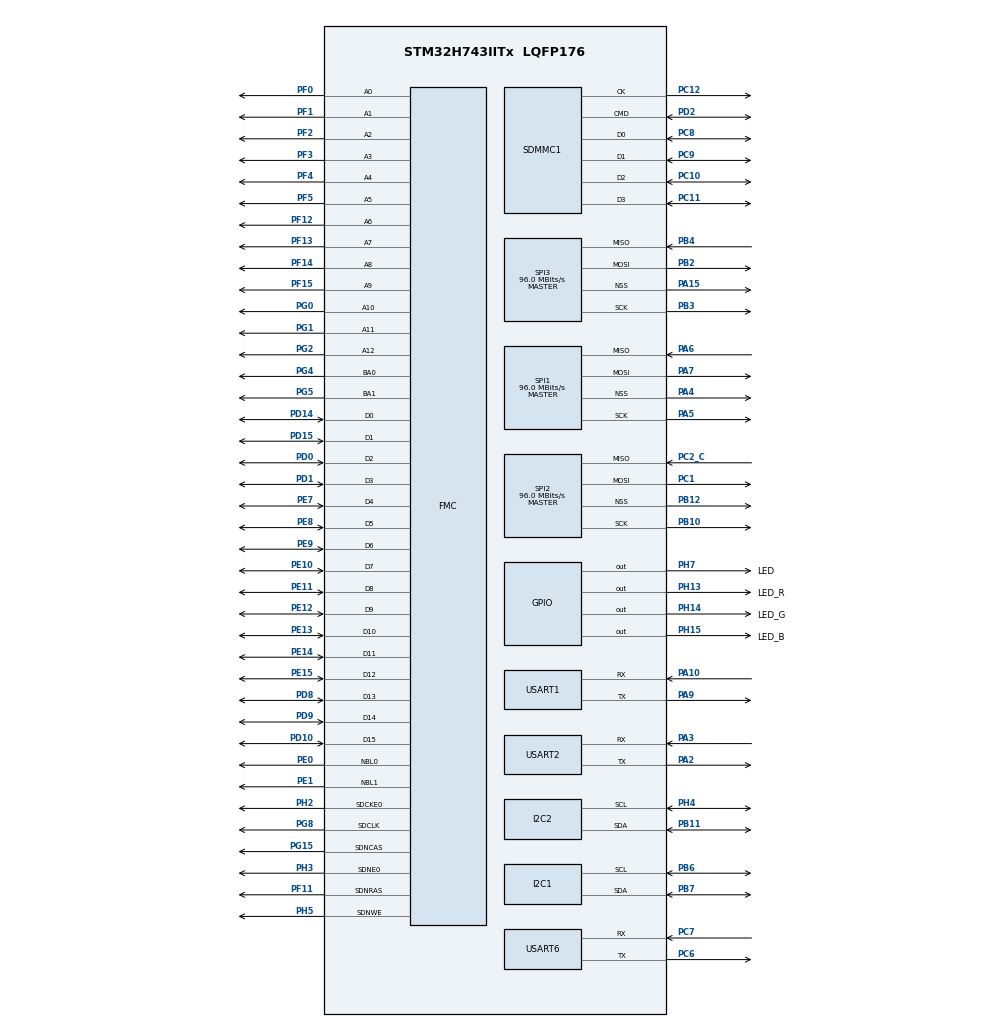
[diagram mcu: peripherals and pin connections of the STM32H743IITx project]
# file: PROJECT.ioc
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CORTEX_M7.CPU_DCache=Enabled
CORTEX_M7.CPU_ICache=Enabled
CORTEX_M7.MPU_Control=MPU_PRIVILEGED_DEFAULT
Dma.Request0=USART1_RX
Dma.Request1=USART1_TX
Dma.USART1_RX.0.Direction=DMA_PERIPH_TO_MEMORY
Dma.USART1_RX.0.EventEnable=DISABLE
Dma.USART1_RX.0.FIFOMode=DMA_FIFOMODE_DISABLE
Dma.USART1_RX.0.Instance=DMA1_Stream0
Dma.USART1_RX.0.MemDataAlignment=DMA_MDATAALIGN_BYTE
Dma.USART1_RX.0.MemInc=DMA_MINC_ENABLE
Dma.USART1_RX.0.Mode=DMA_NORMAL
Dma.USART1_RX.0.PeriphDataAlignment=DMA_PDATAALIGN_BYTE
Dma.USART1_RX.0.PeriphInc=DMA_PINC_DISABLE
Dma.USART1_RX.0.Polarity=HAL_DMAMUX_REQ_GEN_RISING
Dma.USART1_RX.0.Priority=DMA_PRIORITY_LOW
Dma.USART1_RX.0.RequestNumber=1
Dma.USART1_RX.0.SignalID=NONE
Dma.USART1_RX.0.SyncEnable=DISABLE
Dma.USART1_RX.0.SyncPolarity=HAL_DMAMUX_SYNC_NO_EVENT
Dma.USART1_RX.0.SyncRequestNumber=1
Dma.USART1_RX.0.SyncSignalID=NONE
Dma.USART1_TX.1.Direction=DMA_MEMORY_TO_PERIPH
Dma.USART1_TX.1.EventEnable=DISABLE
Dma.USART1_TX.1.FIFOMode=DMA_FIFOMODE_DISABLE
Dma.USART1_TX.1.Instance=DMA1_Stream1
Dma.USART1_TX.1.MemDataAlignment=DMA_MDATAALIGN_BYTE
Dma.USART1_TX.1.MemInc=DMA_MINC_ENABLE
Dma.USART1_TX.1.Mode=DMA_NORMAL
Dma.USART1_TX.1.PeriphDataAlignment=DMA_PDATAALIGN_BYTE
Dma.USART1_TX.1.PeriphInc=DMA_PINC_DISABLE
Dma.USART1_TX.1.Polarity=HAL_DMAMUX_REQ_GEN_RISING
Dma.USART1_TX.1.Priority=DMA_PRIORITY_LOW
Dma.USART1_TX.1.RequestNumber=1
Dma.USART1_TX.1.SignalID=NONE
Dma.USART1_TX.1.SyncEnable=DISABLE
Dma.USART1_TX.1.SyncPolarity=HAL_DMAMUX_SYNC_NO_EVENT
Dma.USART1_TX.1.SyncRequestNumber=1
Dma.USART1_TX.1.SyncSignalID=NONE
FATFS.USE_DMA_CODE_SD=1
FATFS._CODE_PAGE=437
FATFS._USE_LFN=2
FMC.CASLatency1=FMC_SDRAM_CAS_LATENCY_3
FMC.ColumnBitsNumber1=FMC_SDRAM_COLUMN_BITS_NUM_9
FMC.ExitSelfRefreshDelay1=9
FMC.LoadToActiveDelay1=1
FMC.RCDDelay1=3
FMC.RPDelay1=3
FMC.ReadBurst1=FMC_SDRAM_RBURST_ENABLE
FMC.RowCycleDelay1=8
FMC.SDClockPeriod1=FMC_SDRAM_CLOCK_PERIOD_2
FMC.SelfRefreshTime1=6
FMC.WriteRecoveryTime1=3
I2C1.Timing=0x307075B1
I2C2.Timing=0x307075B1
Mcu.Family=STM32H7
Mcu.Name=STM32H743IITx
Mcu.Package=LQFP176
Mdma.MDMA_Channel0.Request0=SDMMC1_END_DATA
Mdma.MDMA_Channel0.RequestsNb=1
Mdma.MDMA_Channel0.SDMMC1_END_DATA.0.BlockCount=0
Mdma.MDMA_Channel0.SDMMC1_END_DATA.0.BlockDataLength=0
Mdma.MDMA_Channel0.SDMMC1_END_DATA.0.BufferTransferLength=1
Mdma.MDMA_Channel0.SDMMC1_END_DATA.0.CircularMode=MDMA_LINEAR_LIST
Mdma.MDMA_Channel0.SDMMC1_END_DATA.0.DataAlignment=MDMA_DATAALIGN_PACKENABLE
Mdma.MDMA_Channel0.SDMMC1_END_DATA.0.DestBlockAddressOffset=0
Mdma.MDMA_Channel0.SDMMC1_END_DATA.0.DestBurst=MDMA_DEST_BURST_SINGLE
Mdma.MDMA_Channel0.SDMMC1_END_DATA.0.DestDataSize=MDMA_DEST_DATASIZE_BYTE
Mdma.MDMA_Channel0.SDMMC1_END_DATA.0.DestinationInc=MDMA_DEST_INC_BYTE
Mdma.MDMA_Channel0.SDMMC1_END_DATA.0.DstAddress=0
Mdma.MDMA_Channel0.SDMMC1_END_DATA.0.Endianness=MDMA_LITTLE_ENDIANNESS_PRESERVE
Mdma.MDMA_Channel0.SDMMC1_END_DATA.0.Instance=MDMA_Channel0
Mdma.MDMA_Channel0.SDMMC1_END_DATA.0.MaskAddress=0
Mdma.MDMA_Channel0.SDMMC1_END_DATA.0.MaskData=0
Mdma.MDMA_Channel0.SDMMC1_END_DATA.0.Priority=MDMA_PRIORITY_LOW
Mdma.MDMA_Channel0.SDMMC1_END_DATA.0.Rank=First
Mdma.MDMA_Channel0.SDMMC1_END_DATA.0.SourceBlockAddressOffset=0
Mdma.MDMA_Channel0.SDMMC1_END_DATA.0.SourceBurst=MDMA_SOURCE_BURST_SINGLE
Mdma.MDMA_Channel0.SDMMC1_END_DATA.0.SourceDataSize=MDMA_SRC_DATASIZE_BYTE
Mdma.MDMA_Channel0.SDMMC1_END_DATA.0.SourceInc=MDMA_SRC_INC_BYTE
Mdma.MDMA_Channel0.SDMMC1_END_DATA.0.SrcAddress=0
Mdma.MDMA_Channel0.SDMMC1_END_DATA.0.TransferTriggerMode=MDMA_BUFFER_TRANSFER
Mdma.RequestSet0=MDMA_Channel0
Mdma.RequestSetsNb=1
NVIC.DMA1_Stream0_IRQn=true\:0\:0\:false\:false\:true\:false\:true\:true
NVIC.DMA1_Stream1_IRQn=true\:0\:0\:false\:false\:true\:false\:true\:true
NVIC.MDMA_IRQn=true\:0\:0\:false\:false\:true\:true\:true\:true
NVIC.PriorityGroup=NVIC_PRIORITYGROUP_4
NVIC.SDMMC1_IRQn=true\:0\:0\:false\:false\:true\:true\:true\:true
NVIC.USART1_IRQn=true\:0\:0\:false\:false\:true\:true\:true\:true
PA10.Mode=Asynchronous
PA10.Signal=USART1_RX
PA13\ (JTMS/SWDIO).Mode=Serial_Wire
PA13\ (JTMS/SWDIO).Signal=DEBUG_JTMS-SWDIO
PA14\ (JTCK/SWCLK).Mode=Serial_Wire
PA14\ (JTCK/SWCLK).Signal=DEBUG_JTCK-SWCLK
PA15\ (JTDI).Mode=NSS_Signal_Hard_Output
PA15\ (JTDI).Signal=SPI3_NSS
PA2.Mode=Asynchronous
PA2.Signal=USART2_TX
PA3.Mode=Asynchronous
PA3.Signal=USART2_RX
PA4.Mode=NSS_Signal_Hard_Output
PA4.Signal=SPI1_NSS
PA5.Mode=Full_Duplex_Master
PA5.Signal=SPI1_SCK
PA6.Mode=Full_Duplex_Master
PA6.Signal=SPI1_MISO
PA7.Mode=Full_Duplex_Master
PA7.Signal=SPI1_MOSI
PA9.Mode=Asynchronous
PA9.Signal=USART1_TX
PB10.Mode=Full_Duplex_Master
PB10.Signal=SPI2_SCK
PB11.Mode=I2C
PB11.Signal=I2C2_SDA
PB12.Mode=NSS_Signal_Hard_Output
PB12.Signal=SPI2_NSS
PB2.Mode=Full_Duplex_Master
PB2.Signal=SPI3_MOSI
PB3\ (JTDO/TRACESWO).Mode=Full_Duplex_Master
PB3\ (JTDO/TRACESWO).Signal=SPI3_SCK
PB4\ (NJTRST).Mode=Full_Duplex_Master
PB4\ (NJTRST).Signal=SPI3_MISO
PB6.Mode=I2C
PB6.Signal=I2C1_SCL
PB7.Mode=I2C
PB7.Signal=I2C1_SDA
PC1.Mode=Full_Duplex_Master
PC1.Signal=SPI2_MOSI
PC10.Mode=SD_4_bits_Wide_bus
PC10.Signal=SDMMC1_D2
PC11.Mode=SD_4_bits_Wide_bus
PC11.Signal=SDMMC1_D3
PC12.Mode=SD_4_bits_Wide_bus
PC12.Signal=SDMMC1_CK
PC14-OSC32_IN\ (OSC32_IN).Mode=LSE-External-Oscillator
PC14-OSC32_IN\ (OSC32_IN).Signal=RCC_OSC32_IN
PC15-OSC32_OUT\ (OSC32_OUT).Mode=LSE-External-Oscillator
PC15-OSC32_OUT\ (OSC32_OUT).Signal=RCC_OSC32_OUT
PC2_C.Mode=Full_Duplex_Master
PC2_C.Signal=SPI2_MISO
PC6.Mode=Asynchronous
PC6.Signal=USART6_TX
PC7.Mode=Asynchronous
PC7.Signal=USART6_RX
PC8.Mode=SD_4_bits_Wide_bus
PC8.Signal=SDMMC1_D0
PC9.Mode=SD_4_bits_Wide_bus
PC9.Signal=SDMMC1_D1
PD0.Signal=FMC_D2_DA2
PD1.Signal=FMC_D3_DA3
PD10.Signal=FMC_D15_DA15
PD14.Signal=FMC_D0_DA0
PD15.Signal=FMC_D1_DA1
PD2.Mode=SD_4_bits_Wide_bus
PD2.Signal=SDMMC1_CMD
PD8.Signal=FMC_D13_DA13
PD9.Signal=FMC_D14_DA14
PE0.Signal=FMC_NBL0
PE1.Signal=FMC_NBL1
PE10.Signal=FMC_D7_DA7
PE11.Signal=FMC_D8_DA8
PE12.Signal=FMC_D9_DA9
PE13.Signal=FMC_D10_DA10
PE14.Signal=FMC_D11_DA11
PE15.Signal=FMC_D12_DA12
PE7.Signal=FMC_D4_DA4
PE8.Signal=FMC_D5_DA5
PE9.Signal=FMC_D6_DA6
PF0.Signal=FMC_A0
PF1.Signal=FMC_A1
PF11.Signal=FMC_SDNRAS
PF12.Signal=FMC_A6
PF13.Signal=FMC_A7
PF14.Signal=FMC_A8
PF15.Signal=FMC_A9
PF2.Signal=FMC_A2
PF3.Signal=FMC_A3
PF4.Signal=FMC_A4
PF5.Signal=FMC_A5
PG0.Signal=FMC_A10
PG1.Signal=FMC_A11
PG15.Signal=FMC_SDNCAS
PG2.Signal=FMC_A12
PG4.Signal=FMC_A14_BA0
PG5.Signal=FMC_A15_BA1
PG8.Signal=FMC_SDCLK
PH0-OSC_IN\ (PH0).Mode=HSE-External-Oscillator
PH0-OSC_IN\ (PH0).Signal=RCC_OSC_IN
PH1-OSC_OUT\ (PH1).Mode=HSE-External-Oscillator
PH1-OSC_OUT\ (PH1).Signal=RCC_OSC_OUT
PH13.GPIO_Label=LED_R
PH13.Signal=GPIO_Output
PH14.GPIO_Label=LED_G
PH14.Signal=GPIO_Output
PH15.GPIO_Label=LED_B
PH15.Signal=GPIO_Output
PH2.Mode=SdramChipSelect1_1
PH2.Signal=FMC_SDCKE0
PH3.Mode=SdramChipSelect1_1
PH3.Signal=FMC_SDNE0
PH4.Mode=I2C
PH4.Signal=I2C2_SCL
PH5.Signal=FMC_SDNWE
PH7.GPIO_Label=LED
PH7.GPIO_PuPd=GPIO_PULLUP
PH7.GPIO_Speed=GPIO_SPEED_FREQ_HIGH
PH7.Signal=GPIO_Output
ProjectManager.HeapSize=0x2000
ProjectManager.StackSize=0x2000
ProjectManager.TargetToolchain=MDK-ARM V5.32
RCC.ADCFreq_Value=50390625
RCC.APB1Freq_Value=120000000
RCC.APB2Freq_Value=120000000
RCC.APB3Freq_Value=120000000
RCC.APB4Freq_Value=120000000
RCC.CortexFreq_Value=480000000
RCC.D1PPRE=RCC_APB3_DIV2
RCC.D2PPRE1=RCC_APB1_DIV2
RCC.D2PPRE2=RCC_APB2_DIV2
RCC.D3PPRE=RCC_APB4_DIV2
RCC.DIVM1=5
RCC.DIVN1=192
RCC.DIVQ1=5
RCC.HCLKFreq_Value=240000000
RCC.HPRE=RCC_HCLK_DIV2
RCC.PLL2FRACN=0
RCC.PLL3FRACN=0
RCC.PLLFRACN=0
RCC.PLLSourceVirtual=RCC_PLLSOURCE_HSE
RCC.SYSCLKFreq_VALUE=480000000
RCC.SYSCLKSource=RCC_SYSCLKSOURCE_PLLCLK
RCC.USBFreq_Value=192000000
SDMMC1.ClockDiv=2
SH.FMC_A0.0=FMC_A0,13b-sda1
SH.FMC_A1.0=FMC_A1,13b-sda1
SH.FMC_A10.0=FMC_A10,13b-sda1
SH.FMC_A11.0=FMC_A11,13b-sda1
SH.FMC_A12.0=FMC_A12,13b-sda1
SH.FMC_A14_BA0.0=FMC_BA0,FourSdramBanks1
SH.FMC_A15_BA1.0=FMC_BA1,FourSdramBanks1
SH.FMC_A2.0=FMC_A2,13b-sda1
SH.FMC_A3.0=FMC_A3,13b-sda1
SH.FMC_A4.0=FMC_A4,13b-sda1
SH.FMC_A5.0=FMC_A5,13b-sda1
SH.FMC_A6.0=FMC_A6,13b-sda1
SH.FMC_A7.0=FMC_A7,13b-sda1
SH.FMC_A8.0=FMC_A8,13b-sda1
SH.FMC_A9.0=FMC_A9,13b-sda1
SH.FMC_D0_DA0.0=FMC_D0,sd-16b-d1
SH.FMC_D10_DA10.0=FMC_D10,sd-16b-d1
SH.FMC_D11_DA11.0=FMC_D11,sd-16b-d1
SH.FMC_D12_DA12.0=FMC_D12,sd-16b-d1
SH.FMC_D13_DA13.0=FMC_D13,sd-16b-d1
SH.FMC_D14_DA14.0=FMC_D14,sd-16b-d1
SH.FMC_D15_DA15.0=FMC_D15,sd-16b-d1
SH.FMC_D1_DA1.0=FMC_D1,sd-16b-d1
SH.FMC_D2_DA2.0=FMC_D2,sd-16b-d1
SH.FMC_D3_DA3.0=FMC_D3,sd-16b-d1
SH.FMC_D4_DA4.0=FMC_D4,sd-16b-d1
SH.FMC_D5_DA5.0=FMC_D5,sd-16b-d1
SH.FMC_D6_DA6.0=FMC_D6,sd-16b-d1
SH.FMC_D7_DA7.0=FMC_D7,sd-16b-d1
SH.FMC_D8_DA8.0=FMC_D8,sd-16b-d1
SH.FMC_D9_DA9.0=FMC_D9,sd-16b-d1
SH.FMC_NBL0.0=FMC_NBL0,Sd2ByteEnable1
SH.FMC_NBL1.0=FMC_NBL1,Sd2ByteEnable1
SH.FMC_SDCLK.0=FMC_SDCLK,13b-sda1
SH.FMC_SDNCAS.0=FMC_SDNCAS,13b-sda1
SH.FMC_SDNRAS.0=FMC_SDNRAS,13b-sda1
SH.FMC_SDNWE.0=FMC_SDNWE,13b-sda1
SPI1.CalculateBaudRate=96.0 MBits/s
SPI1.Direction=SPI_DIRECTION_2LINES
SPI1.Mode=SPI_MODE_MASTER
SPI1.VirtualNSS=VM_NSSHARD
SPI1.VirtualType=VM_MASTER
SPI2.CalculateBaudRate=96.0 MBits/s
SPI2.Direction=SPI_DIRECTION_2LINES
SPI2.Mode=SPI_MODE_MASTER
SPI2.VirtualNSS=VM_NSSHARD
SPI2.VirtualType=VM_MASTER
SPI3.CalculateBaudRate=96.0 MBits/s
SPI3.Direction=SPI_DIRECTION_2LINES
SPI3.Mode=SPI_MODE_MASTER
SPI3.VirtualNSS=VM_NSSHARD
SPI3.VirtualType=VM_MASTER
USART1.VirtualMode-Asynchronous=VM_ASYNC
USART2.VirtualMode-Asynchronous=VM_ASYNC
USART6.VirtualMode-Asynchronous=VM_ASYNC
VP_FATFS_VS_SDIO.Mode=SDIO
VP_RTC_VS_RTC_Activate.Mode=RTC_Enabled
VP_RTC_VS_RTC_Calendar.Mode=RTC_Calendar
board=custom

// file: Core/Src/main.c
/* USER CODE BEGIN Header */
/**
 ******************************************************************************
 * @file           : main.c
 * @brief          : Main program body
 ******************************************************************************
 * @attention
 *
 * Copyright (c) 2024 STMicroelectronics.
 * All rights reserved.
 *
 * This software is licensed under terms that can be found in the LICENSE file
 * in the root directory of this software component.
 * If no LICENSE file comes with this software, it is provided AS-IS.
 *
 ******************************************************************************
 */
/* USER CODE END Header */
#include "main.h"
#include "dma.h"
#include "fatfs.h"
#include "i2c.h"
#include "mdma.h"
#include "rtc.h"
#include "sdmmc.h"
#include "spi.h"
#include "usart.h"
#include "gpio.h"
#include "fmc.h"

/* USER CODE BEGIN Includes */
#include "setup.h"

/* USER CODE END Includes */

void SystemClock_Config(void);
static void MPU_Config(void);

int main(void)
{

  /* MPU Configuration--------------------------------------------------------*/
  MPU_Config();
/* Enable the CPU Cache */

  /* Enable I-Cache---------------------------------------------------------*/
  SCB_EnableICache();

  /* Enable D-Cache---------------------------------------------------------*/
  SCB_EnableDCache();

  /* MCU Configuration--------------------------------------------------------*/

  /* Reset of all peripherals, Initializes the Flash interface and the Systick. */
  HAL_Init();

  /* Configure the system clock */
  SystemClock_Config();

  /* Initialize all configured peripherals */
  MX_GPIO_Init();
  MX_MDMA_Init();
  MX_DMA_Init();
  MX_USART1_UART_Init();
  MX_SDMMC1_SD_Init();
  MX_FATFS_Init();
  MX_FMC_Init();
  MX_RTC_Init();
  MX_I2C1_Init();
  MX_I2C2_Init();
  MX_SPI1_Init();
  MX_SPI2_Init();
  MX_SPI3_Init();
  MX_USART2_UART_Init();
  MX_USART6_UART_Init();
  /* USER CODE BEGIN 2 */
  Node_Init();
  MPU6050_Gravity_Projection(&IMU_Calibration_Instance);

  /* USER CODE END 2 */

  /* Infinite loop */
  while (1)
  {

  }
}

void SystemClock_Config(void)
{
  RCC_OscInitTypeDef RCC_OscInitStruct = {0};
  RCC_ClkInitTypeDef RCC_ClkInitStruct = {0};

  /** Supply configuration update enable
  */
  HAL_PWREx_ConfigSupply(PWR_LDO_SUPPLY);

  /** Configure the main internal regulator output voltage
  */
  __HAL_PWR_VOLTAGESCALING_CONFIG(PWR_REGULATOR_VOLTAGE_SCALE1);

  while(!__HAL_PWR_GET_FLAG(PWR_FLAG_VOSRDY)) {}

  __HAL_RCC_SYSCFG_CLK_ENABLE();
  __HAL_PWR_VOLTAGESCALING_CONFIG(PWR_REGULATOR_VOLTAGE_SCALE0);

  while(!__HAL_PWR_GET_FLAG(PWR_FLAG_VOSRDY)) {}

  /** Initializes the RCC Oscillators according to the specified parameters
  * in the RCC_OscInitTypeDef structure.
  */
  RCC_OscInitStruct.OscillatorType = RCC_OSCILLATORTYPE_LSI|RCC_OSCILLATORTYPE_HSE;
  RCC_OscInitStruct.HSEState = RCC_HSE_ON;
  RCC_OscInitStruct.LSIState = RCC_LSI_ON;
  RCC_OscInitStruct.PLL.PLLState = RCC_PLL_ON;
  RCC_OscInitStruct.PLL.PLLSource = RCC_PLLSOURCE_HSE;
  RCC_OscInitStruct.PLL.PLLM = 5;
  RCC_OscInitStruct.PLL.PLLN = 192;
  RCC_OscInitStruct.PLL.PLLP = 2;
  RCC_OscInitStruct.PLL.PLLQ = 5;
  RCC_OscInitStruct.PLL.PLLR = 2;
  RCC_OscInitStruct.PLL.PLLRGE = RCC_PLL1VCIRANGE_2;
  RCC_OscInitStruct.PLL.PLLVCOSEL = RCC_PLL1VCOWIDE;
  RCC_OscInitStruct.PLL.PLLFRACN = 0;
  if (HAL_RCC_OscConfig(&RCC_OscInitStruct) != HAL_OK)
  {
    Error_Handler();
  }

  /** Initializes the CPU, AHB and APB buses clocks
  */
  RCC_ClkInitStruct.ClockType = RCC_CLOCKTYPE_HCLK|RCC_CLOCKTYPE_SYSCLK
                              |RCC_CLOCKTYPE_PCLK1|RCC_CLOCKTYPE_PCLK2
                              |RCC_CLOCKTYPE_D3PCLK1|RCC_CLOCKTYPE_D1PCLK1;
  RCC_ClkInitStruct.SYSCLKSource = RCC_SYSCLKSOURCE_PLLCLK;
  RCC_ClkInitStruct.SYSCLKDivider = RCC_SYSCLK_DIV1;
  RCC_ClkInitStruct.AHBCLKDivider = RCC_HCLK_DIV2;
  RCC_ClkInitStruct.APB3CLKDivider = RCC_APB3_DIV2;
  RCC_ClkInitStruct.APB1CLKDivider = RCC_APB1_DIV2;
  RCC_ClkInitStruct.APB2CLKDivider = RCC_APB2_DIV2;
  RCC_ClkInitStruct.APB4CLKDivider = RCC_APB4_DIV2;

  if (HAL_RCC_ClockConfig(&RCC_ClkInitStruct, FLASH_LATENCY_4) != HAL_OK)
  {
    Error_Handler();
  }
}

/* MPU Configuration */

void MPU_Config(void)
{

  /* Disables the MPU */
  HAL_MPU_Disable();
  /* Enables the MPU */
  HAL_MPU_Enable(MPU_PRIVILEGED_DEFAULT);

}

void Error_Handler(void)
{
  __disable_irq();
  while (1)
  {
  }
}
